# Template register map
Vendor: VendorName Co.Ltd; Series: SeriesName; File version: 1.2
CPU: CM7 r0p1, little endian, MPU, FPU, 4 interrupt priority bits
Registers are 32-bit, read-write, no defined reset value unless marked. A register's access mark holds for its fields unless they carry their own. Offsets are from the block's base; [hi:lo] are bit positions.

## I2C1 — Inter-Integrated Circuit 1
Base 0x40048000
Same registers: I2C2 0x40063000
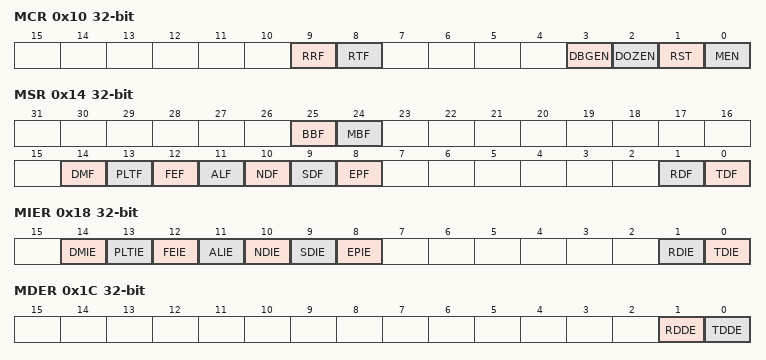
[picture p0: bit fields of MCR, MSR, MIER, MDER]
0x10 MCR — I2C master control register
  [9] RRF wo — I2C RRF bit: reset receive FIFO
  [8] RTF wo — I2C RTF bit: reset transmit FIFO
  [3] DBGEN — I2C DBGEN bit: debug enable
  [2] DOZEN — I2C DOZEN bit: doze mode enable
  [1] RST — I2C RST bit: I2C master software reset control
  [0] MEN — I2C MEN bit: I2C master enable
0x14 MSR — I2C master status register
  [25] BBF ro — I2C BBF bit: bus busy flag
  [24] MBF ro — I2C MBF bit: master busy flag
  [14] DMF — I2C DMF bit: data match flag
  [13] PLTF — I2C PLTF bit: pin low timeout flag
  [12] FEF — I2C FEF bit: FIFO error flag
  [11] ALF — I2C ALF bit: arbitration lost flag
  [10] NDF — I2C NDF bit: NACK detect flag
  [9] SDF — I2C SDF bit: STOP detect flag
  [8] EPF — I2C EPF bit: end packet flag
  [1] RDF ro — I2C RDF bit: receive data flag
  [0] TDF ro — I2C TDF bit: transmit data flag
0x18 MIER — I2C master interrupt enable register
  [14] DMIE — I2C DMIE bit: data match interrupt enable
  [13] PLTIE — I2C PLTIE bit: pin low timeout interrupt enable
  [12] FEIE — I2C FEIE bit: FIFO error interrupt enable
  [11] ALIE — I2C ALIE bit: arbitration lost interrupt enable
  [10] NDIE — I2C NDIE bit: NACK detect interrupt enable
  [9] SDIE — I2C SDIE bit: STOP detect interrupt enable
  [8] EPIE — I2C EPIE bit: end packet interrupt enable
  [1] RDIE — I2C RDIE bit: receive data interrupt enable
  [0] TDIE — I2C TDIE bit: transmit data interrupt enable
0x1C MDER — I2C master DMA enable register
  [1] RDDE — I2C RDDE bit: receive data DMA enable
  [0] TDDE — I2C TDDE bit: transmit data DMA enable
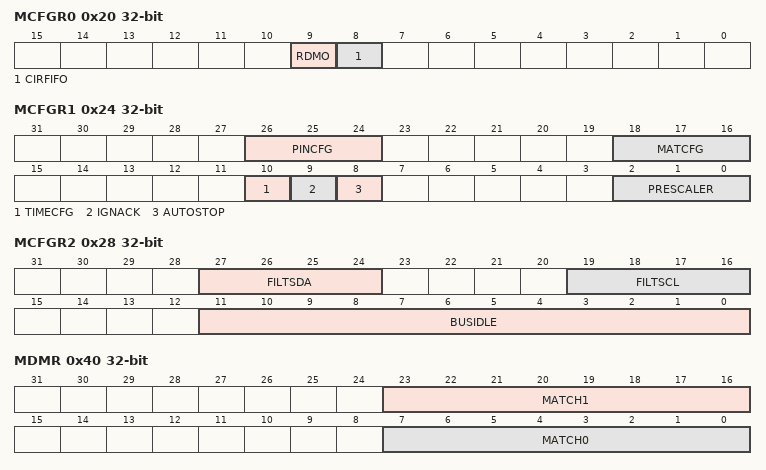
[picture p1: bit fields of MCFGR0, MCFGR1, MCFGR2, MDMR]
0x20 MCFGR0 — I2C master configuration 0 register
  [9] RDMO — I2C RDMO bit: receive data match only
  [8] CIRFIFO — I2C CIRFIFO bit: circular FIFO enable
0x24 MCFGR1 — I2C master configuration 1 register
  [26:24] PINCFG — I2C PINCFG[2:0] bit: pin configuration
  [18:16] MATCFG — I2C MATCFG[2:0] bit: match configuration
  [10] TIMECFG — I2C TIMECFG bit: timeout configuration
  [9] IGNACK — I2C IGNACK bit: ignore NACK enable control
  [8] AUTOSTOP — I2C AUTOSTOP bit: automatic STOP generation
  [2:0] PRESCALER — I2C PRESCALER[2:0] bit: prescaler configuration
0x28 MCFGR2 — I2C master configuration 2 register
  [27:24] FILTSDA — I2C FILTSDA[3:0] bit: glitch filter SDA
  [19:16] FILTSCL — I2C FILTSCL[3:0] bit: glitch filter SCL
  [11:0] BUSIDLE — I2C BUSIDLE[11:0] bit: bus idle timeout
0x2C MCFGR3 — I2C master configuration 3 register
  [19:8] PINLOW — I2C PINLOW[11:0] bit: pin low timeout
0x40 MDMR — I2C master data match register
  [23:16] MATCH1 — I2C MATCH1[7:0] bit: match 0 value
  [7:0] MATCH0 — I2C MATCH0[7:0] bit: match 1 value
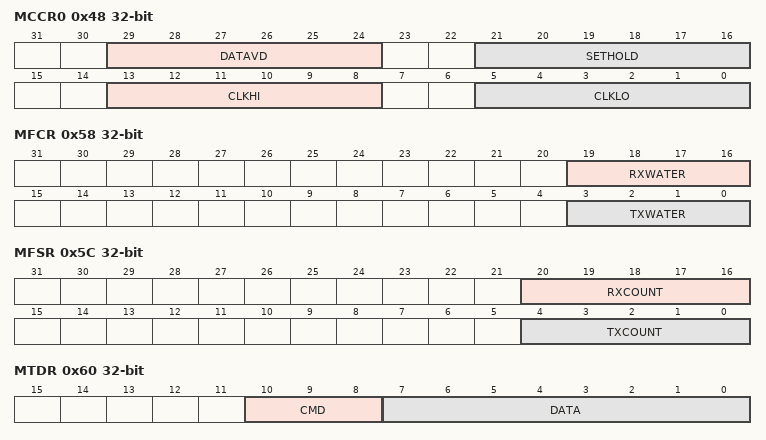
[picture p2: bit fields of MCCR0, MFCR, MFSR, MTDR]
0x48 MCCR0 — I2C master clock configuration 0 register
  [29:24] DATAVD — I2C DATAVD[5:0] bit: data valid delay
  [21:16] SETHOLD — I2C SETHOLD[5:0] bit: setup hold delay
  [13:8] CLKHI — I2C CLKHI[5:0] bit: clock high period
  [5:0] CLKLO — I2C CLKLO[5:0] bit: clock low period
0x58 MFCR — I2C master FIFO control register
  [19:16] RXWATER — I2C RXWATER[3:0] bit: receive FIFO watermark
  [3:0] TXWATER — I2C TXWATER[3:0] bit: transmit FIFO watermark
0x5C MFSR ro — I2C master FIFO status register
  [20:16] RXCOUNT — I2C RXCOUNT[4:0] bit: receive FIFO count
  [4:0] TXCOUNT — I2C TXCOUNT[4:0] bit: transmit FIFO count
0x60 MTDR wo — I2C master transmit data register
  [10:8] CMD — I2C CMD[2:0] bit: command data
  [7:0] DATA — I2C DATA[7:0] bit: transmit data
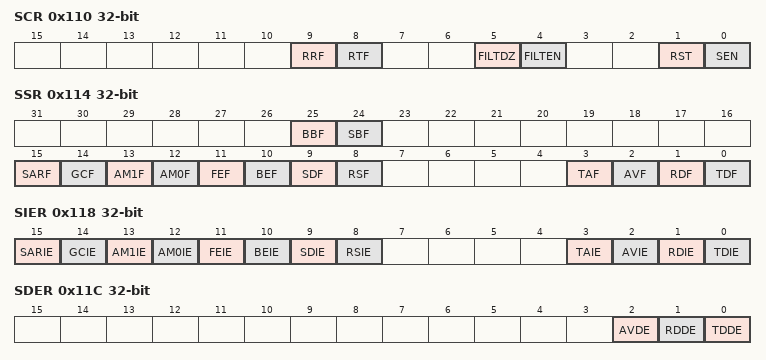
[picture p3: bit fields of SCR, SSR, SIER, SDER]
0x110 SCR — I2C slave control register
  [9] RRF wo — I2C RRF bit: reset receive FIFO
  [8] RTF wo — I2C RTF bit: reset transmit FIFO
  [5] FILTDZ — I2C FILTDZ bit: filter doze enable
  [4] FILTEN — I2C FILTEN bit: filter enable
  [1] RST — I2C RST bit: software reset
  [0] SEN — I2C SEN bit: slave enable
0x114 SSR — I2C slave status register
  [25] BBF ro — I2C BBF bit: bus busy flag
  [24] SBF ro — I2C SBF bit: slave busy flag
  [15] SARF ro — I2C SARF bit: SMBus alert response flag
  [14] GCF ro — I2C GCF bit: general call flag
  [13] AM1F ro — I2C AM1F bit: address match 1 flag
  [12] AM0F ro — I2C AM0F bit: address match 0 flag
  [11] FEF — I2C FEF bit: FIFO error flag
  [10] BEF — I2C BEF bit: bit error flag
  [9] SDF — I2C SDF bit: STOP detect flag
  [8] RSF — I2C RSF bit: repeated start flag
  [3] TAF ro — I2C TAF bit: transmit ACK flag
  [2] AVF ro — I2C AVF bit: address valid flag
  [1] RDF ro — I2C RDF bit: receive data flag
  [0] TDF ro — I2C TDF bit: transmit data flag
0x118 SIER — I2C slave interrupt enable register
  [15] SARIE — I2C SARIE bit: SMBus alert response interrupt enable
  [14] GCIE — I2C GCIE bit: general call interrupt enable
  [13] AM1IE — I2C AM1IE bit: address match 1 interrupt enable
  [12] AM0IE — I2C AM0IE bit: address match 0 interrupt enable
  [11] FEIE — I2C FEIE bit: FIFO error interrupt enable
  [10] BEIE — I2C BEIE bit: bit error interrupt enable
  [9] SDIE — I2C SDIE bit: STOP detect interrupt enable
  [8] RSIE — I2C RSIE bit: repeated start interrupt enable
  [3] TAIE — I2C TAIE bit: transmit ACK interrupt enable
  [2] AVIE — I2C AVIE bit: address valid interrupt enable
  [1] RDIE — I2C RDIE bit: receive data interrupt enable
  [0] TDIE — I2C TDIE bit: transmit data interrupt enable
0x11C SDER — I2C slave DMA enable register
  [2] AVDE — I2C AVDE bit: address valid DMA enable
  [1] RDDE — I2C RDDE bit: receive data DMA enable
  [0] TDDE — I2C TDDE bit: transmit data DMA enable
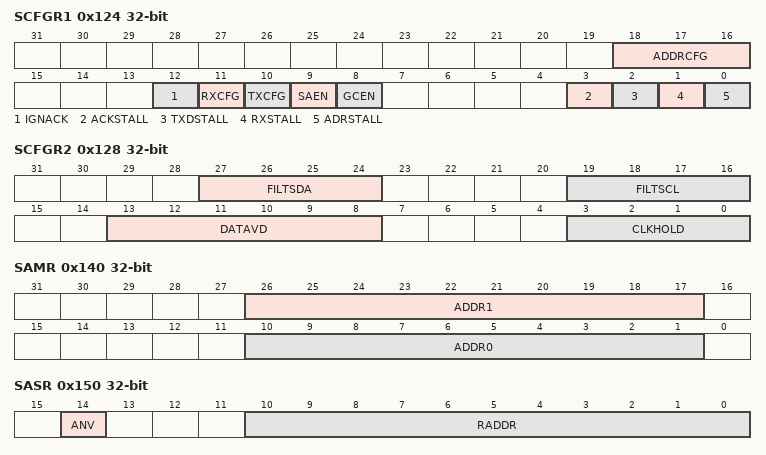
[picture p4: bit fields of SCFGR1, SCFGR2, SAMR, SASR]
0x124 SCFGR1 — I2C slave configuration 1 register
  [18:16] ADDRCFG — I2C ADDRCFG[2:0] bit: address configuration
  [12] IGNACK — I2C IGNACK bit: ignore NACK
  [11] RXCFG — I2C RXCFG bit: receive data configuration
  [10] TXCFG — I2C TXCFG bit: transmit flag configuration
  [9] SAEN — I2C SAEN bit: SMBus alert enable
  [8] GCEN — I2C GCEN bit: general call enable
  [3] ACKSTALL — I2C ACKSTALL bit: ACK SCL stall
  [2] TXDSTALL — I2C TXDSTALL bit: TX data SCL stall
  [1] RXSTALL — I2C RXSTALL bit: RX SCL stall
  [0] ADRSTALL — I2C ADRSTALL bit: address SCL stall
0x128 SCFGR2 — I2C slave configuration 2 register
  [27:24] FILTSDA — I2C FILTSDA[3:0] bit: glitch filter SDA
  [19:16] FILTSCL — I2C FILTSCL[3:0] bit: glitch filter SCL
  [13:8] DATAVD — I2C DATAVD[5:0] bit: data valid delay
  [3:0] CLKHOLD — I2C CLKHOLD[3:0] bit: clock hold time
0x140 SAMR — I2C slave address match register
  [26:17] ADDR1 — I2C ADDR1[9:0] bit: address 1 value
  [10:1] ADDR0 — I2C ADDR0[9:0] bit: address 0 value
0x150 SASR ro — I2C slave address status register
  [14] ANV — I2C ANV bit: address match status
  [10:0] RADDR — I2C RADDR[10:0] bit: received address value and RW bit
0x154 STAR — I2C slave transmit ACK register
  [0] TXNACK — I2C TXNACK bit: transmit NACK
0x160 STDR wo — I2C slave transmit data register
  [7:0] DATA — I2C DATA[7:0] bit: data to be transmitted to bus
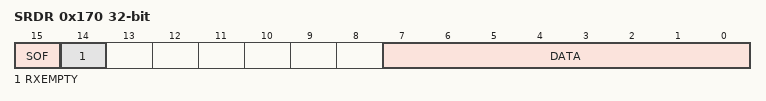
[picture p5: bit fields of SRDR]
0x170 SRDR ro — I2C slave receive data register
  [15] SOF — I2C SOF bit: start of frame
  [14] RXEMPTY — I2C RXEMPTY bit: RX empty
  [7:0] DATA — I2C DATA[7:0] bit: receive data
